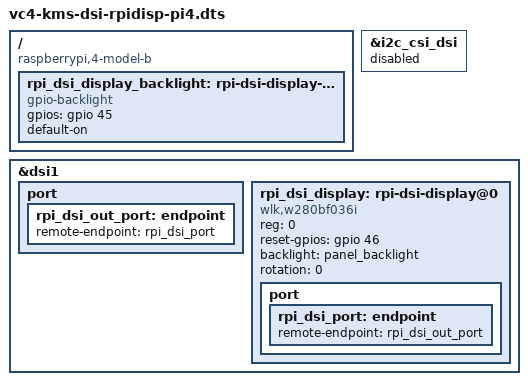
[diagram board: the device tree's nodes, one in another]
/dts-v1/;
/plugin/;
/ {
	compatible = "raspberrypi,4-model-b","brcm,bcm2711";
	
	fragment@0 {
		target-path="/";
		__overlay__ {
			rpi_dsi_display_backlight:rpi-dsi-display-backlight {
				compatible = "gpio-backlight";
				gpios = <&gpio 45 0>;
				default-on;
			};
		};
	};
	
	fragment@1 {
		target = <&i2c_csi_dsi>;
		__overlay__ {
			status = "disabled";
		};
	};

	fragment@2 {
		target = <&dsi1>;
		__overlay__{
			status = "okay";
			#address-cells = <1>;
			#size-cells = <0>;
			port {
				rpi_dsi_out_port:endpoint {
					remote-endpoint = <&rpi_dsi_port>;
				};
			};
			
			rpi_dsi_display:rpi-dsi-display@0 {
				compatible    = "wlk,w280bf036i";
				status        = "okay";
				reg           = <0>;
				// reset-gpios   = <&gpio 44 0>;
				reset-gpios   = <&gpio 46 0>;// fix me
				backlight = <&panel_backlight>;
				rotation = <0>;
				port {
					rpi_dsi_port: endpoint {
						remote-endpoint = <&rpi_dsi_out_port>;
					};
				};
			};
		};
	};
};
